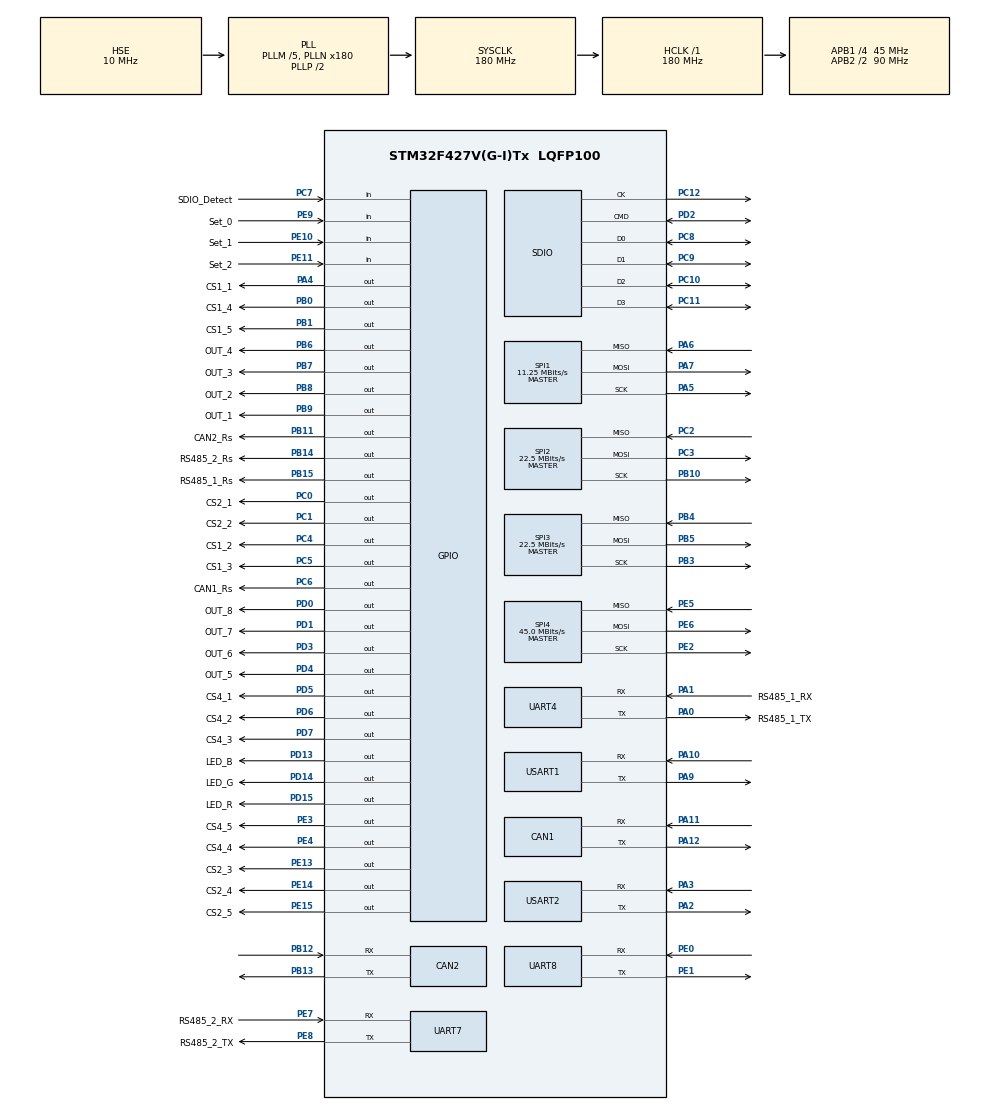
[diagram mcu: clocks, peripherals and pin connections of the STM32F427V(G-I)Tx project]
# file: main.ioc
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CAN1.BS1=CAN_BS1_1TQ
CAN1.BS2=CAN_BS2_1TQ
CAN1.CalculateTimeQuantum=355.55555555555554
CAN2.BS1=CAN_BS1_1TQ
CAN2.BS2=CAN_BS2_1TQ
CAN2.CalculateTimeQuantum=355.55555555555554
FATFS.BSP.number=1
FATFS0.BSP.STBoard=false
FATFS0.BSP.api=Unknown
FATFS0.BSP.i2caddr=0
FATFS0.BSP.instance=PC7
FATFS0.BSP.ip=GPIO
FATFS0.BSP.mode=Input
FATFS0.BSP.name=Detect_SDIO
FATFS0.BSP.solution=PC7
FREERTOS.Tasks01=defaultTask,0,128,StartDefaultTask,Default,NULL,Dynamic,NULL,NULL;ModBusTask,0,256,StartModBusTask,Default,NULL,Dynamic,NULL,NULL
Mcu.Family=STM32F4
Mcu.Name=STM32F427V(G-I)Tx
Mcu.Package=LQFP100
NVIC.PriorityGroup=NVIC_PRIORITYGROUP_4
NVIC.TIM2_IRQn=true\:5\:0\:false\:false\:true\:true\:true\:true
NVIC.TIM8_TRG_COM_TIM14_IRQn=true\:0\:0\:false\:false\:true\:false\:false\:true
NVIC.TimeBase=TIM8_TRG_COM_TIM14_IRQn
NVIC.TimeBaseIP=TIM14
NVIC.UART4_IRQn=true\:5\:0\:false\:false\:true\:true\:true\:true
NVIC.UART7_IRQn=true\:5\:0\:false\:false\:true\:true\:true\:true
PA0/WKUP.GPIO_Label=RS485_1_TX
PA0/WKUP.Mode=Asynchronous
PA0/WKUP.Signal=UART4_TX
PA1.GPIO_Label=RS485_1_RX
PA1.Mode=Asynchronous
PA1.Signal=UART4_RX
PA10.Mode=Asynchronous
PA10.Signal=USART1_RX
PA11.Mode=Master
PA11.Signal=CAN1_RX
PA12.Mode=Master
PA12.Signal=CAN1_TX
PA13.Mode=Serial_Wire
PA13.Signal=SYS_JTMS-SWDIO
PA14.Mode=Serial_Wire
PA14.Signal=SYS_JTCK-SWCLK
PA2.Mode=Asynchronous
PA2.Signal=USART2_TX
PA3.Mode=Asynchronous
PA3.Signal=USART2_RX
PA4.GPIO_Label=CS1_1
PA4.GPIO_Speed=GPIO_SPEED_FREQ_VERY_HIGH
PA4.PinState=GPIO_PIN_SET
PA4.Signal=GPIO_Output
PA5.Mode=Full_Duplex_Master
PA5.Signal=SPI1_SCK
PA6.Mode=Full_Duplex_Master
PA6.Signal=SPI1_MISO
PA7.Mode=Full_Duplex_Master
PA7.Signal=SPI1_MOSI
PA9.Mode=Asynchronous
PA9.Signal=USART1_TX
PB0.GPIO_Label=CS1_4
PB0.GPIO_Speed=GPIO_SPEED_FREQ_VERY_HIGH
PB0.PinState=GPIO_PIN_SET
PB0.Signal=GPIO_Output
PB1.GPIO_Label=CS1_5
PB1.GPIO_Speed=GPIO_SPEED_FREQ_VERY_HIGH
PB1.PinState=GPIO_PIN_SET
PB1.Signal=GPIO_Output
PB10.Mode=Full_Duplex_Master
PB10.Signal=SPI2_SCK
PB11.GPIO_Label=CAN2_Rs
PB11.Signal=GPIO_Output
PB12.Mode=Slave
PB12.Signal=CAN2_RX
PB13.Mode=Slave
PB13.Signal=CAN2_TX
PB14.GPIO_Label=RS485_2_Rs
PB14.GPIO_Speed=GPIO_SPEED_FREQ_VERY_HIGH
PB14.Signal=GPIO_Output
PB15.GPIO_Label=RS485_1_Rs
PB15.GPIO_Speed=GPIO_SPEED_FREQ_VERY_HIGH
PB15.Signal=GPIO_Output
PB3.Mode=Full_Duplex_Master
PB3.Signal=SPI3_SCK
PB4.Mode=Full_Duplex_Master
PB4.Signal=SPI3_MISO
PB5.Mode=Full_Duplex_Master
PB5.Signal=SPI3_MOSI
PB6.GPIO_Label=OUT_4
PB6.Signal=GPIO_Output
PB7.GPIO_Label=OUT_3
PB7.Signal=GPIO_Output
PB8.GPIO_Label=OUT_2
PB8.Signal=GPIO_Output
PB9.GPIO_Label=OUT_1
PB9.Signal=GPIO_Output
PC0.GPIO_Label=CS2_1
PC0.GPIO_Speed=GPIO_SPEED_FREQ_VERY_HIGH
PC0.PinState=GPIO_PIN_SET
PC0.Signal=GPIO_Output
PC1.GPIO_Label=CS2_2
PC1.GPIO_Speed=GPIO_SPEED_FREQ_VERY_HIGH
PC1.PinState=GPIO_PIN_SET
PC1.Signal=GPIO_Output
PC10.GPIO_PuPd=GPIO_PULLUP
PC10.Mode=SD_4_bits_Wide_bus
PC10.Signal=SDIO_D2
PC11.GPIO_PuPd=GPIO_PULLUP
PC11.Mode=SD_4_bits_Wide_bus
PC11.Signal=SDIO_D3
PC12.Mode=SD_4_bits_Wide_bus
PC12.Signal=SDIO_CK
PC14/OSC32_IN.Mode=LSE-External-Oscillator
PC14/OSC32_IN.Signal=RCC_OSC32_IN
PC15/OSC32_OUT.Mode=LSE-External-Oscillator
PC15/OSC32_OUT.Signal=RCC_OSC32_OUT
PC2.Mode=Full_Duplex_Master
PC2.Signal=SPI2_MISO
PC3.Mode=Full_Duplex_Master
PC3.Signal=SPI2_MOSI
PC4.GPIO_Label=CS1_2
PC4.GPIO_Speed=GPIO_SPEED_FREQ_VERY_HIGH
PC4.PinState=GPIO_PIN_SET
PC4.Signal=GPIO_Output
PC5.GPIO_Label=CS1_3
PC5.GPIO_Speed=GPIO_SPEED_FREQ_VERY_HIGH
PC5.PinState=GPIO_PIN_SET
PC5.Signal=GPIO_Output
PC6.GPIO_Label=CAN1_Rs
PC6.Signal=GPIO_Output
PC7.GPIO_Label=SDIO_Detect
PC7.GPIO_PuPd=GPIO_PULLUP
PC7.Signal=GPIO_Input
PC8.GPIO_PuPd=GPIO_PULLUP
PC8.Mode=SD_4_bits_Wide_bus
PC8.Signal=SDIO_D0
PC9.GPIO_PuPd=GPIO_PULLUP
PC9.Mode=SD_4_bits_Wide_bus
PC9.Signal=SDIO_D1
PD0.GPIO_Label=OUT_8
PD0.Signal=GPIO_Output
PD1.GPIO_Label=OUT_7
PD1.Signal=GPIO_Output
PD13.GPIO_Label=LED_B
PD13.PinState=GPIO_PIN_SET
PD13.Signal=GPIO_Output
PD14.GPIO_Label=LED_G
PD14.PinState=GPIO_PIN_RESET
PD14.Signal=GPIO_Output
PD15.GPIO_Label=LED_R
PD15.PinState=GPIO_PIN_SET
PD15.Signal=GPIO_Output
PD2.GPIO_PuPd=GPIO_PULLUP
PD2.Mode=SD_4_bits_Wide_bus
PD2.Signal=SDIO_CMD
PD3.GPIO_Label=OUT_6
PD3.Signal=GPIO_Output
PD4.GPIO_Label=OUT_5
PD4.Signal=GPIO_Output
PD5.GPIO_Label=CS4_1
PD5.GPIO_Speed=GPIO_SPEED_FREQ_VERY_HIGH
PD5.PinState=GPIO_PIN_SET
PD5.Signal=GPIO_Output
PD6.GPIO_Label=CS4_2
PD6.GPIO_Speed=GPIO_SPEED_FREQ_VERY_HIGH
PD6.PinState=GPIO_PIN_SET
PD6.Signal=GPIO_Output
PD7.GPIO_Label=CS4_3
PD7.GPIO_Speed=GPIO_SPEED_FREQ_VERY_HIGH
PD7.PinState=GPIO_PIN_SET
PD7.Signal=GPIO_Output
PE0.Mode=Asynchronous
PE0.Signal=UART8_RX
PE1.Mode=Asynchronous
PE1.Signal=UART8_TX
PE10.GPIO_Label=Set_1
PE10.GPIO_PuPd=GPIO_PULLUP
PE10.Signal=GPIO_Input
PE11.GPIO_Label=Set_2
PE11.GPIO_PuPd=GPIO_PULLUP
PE11.Signal=GPIO_Input
PE13.GPIO_Label=CS2_3
PE13.GPIO_Speed=GPIO_SPEED_FREQ_VERY_HIGH
PE13.PinState=GPIO_PIN_SET
PE13.Signal=GPIO_Output
PE14.GPIO_Label=CS2_4
PE14.GPIO_Speed=GPIO_SPEED_FREQ_VERY_HIGH
PE14.PinState=GPIO_PIN_SET
PE14.Signal=GPIO_Output
PE15.GPIO_Label=CS2_5
PE15.GPIO_Speed=GPIO_SPEED_FREQ_VERY_HIGH
PE15.PinState=GPIO_PIN_SET
PE15.Signal=GPIO_Output
PE2.Mode=Full_Duplex_Master
PE2.Signal=SPI4_SCK
PE3.GPIO_Label=CS4_5
PE3.GPIO_Speed=GPIO_SPEED_FREQ_VERY_HIGH
PE3.PinState=GPIO_PIN_SET
PE3.Signal=GPIO_Output
PE4.GPIO_Label=CS4_4
PE4.GPIO_Speed=GPIO_SPEED_FREQ_VERY_HIGH
PE4.PinState=GPIO_PIN_SET
PE4.Signal=GPIO_Output
PE5.Mode=Full_Duplex_Master
PE5.Signal=SPI4_MISO
PE6.Mode=Full_Duplex_Master
PE6.Signal=SPI4_MOSI
PE7.GPIO_Label=RS485_2_RX
PE7.Mode=Asynchronous
PE7.Signal=UART7_RX
PE8.GPIO_Label=RS485_2_TX
PE8.Mode=Asynchronous
PE8.Signal=UART7_TX
PE9.GPIO_Label=Set_0
PE9.GPIO_PuPd=GPIO_PULLUP
PE9.Signal=GPIO_Input
PH0/OSC_IN.Mode=HSE-External-Oscillator
PH0/OSC_IN.Signal=RCC_OSC_IN
PH1/OSC_OUT.Mode=HSE-External-Oscillator
PH1/OSC_OUT.Signal=RCC_OSC_OUT
ProjectManager.HeapSize=0x200
ProjectManager.StackSize=0x400
ProjectManager.TargetToolchain=MDK-ARM V5.27
RCC.48MHZClocksFreq_Value=45000000
RCC.AHBFreq_Value=180000000
RCC.APB1CLKDivider=RCC_HCLK_DIV4
RCC.APB1Freq_Value=45000000
RCC.APB1TimFreq_Value=90000000
RCC.APB2CLKDivider=RCC_HCLK_DIV2
RCC.APB2Freq_Value=90000000
RCC.APB2TimFreq_Value=180000000
RCC.CortexFreq_Value=180000000
RCC.HCLKFreq_Value=180000000
RCC.HSE_VALUE=10000000
RCC.HSI_VALUE=16000000
RCC.PLLM=5
RCC.PLLN=180
RCC.PLLQ=8
RCC.PLLSourceVirtual=RCC_PLLSOURCE_HSE
RCC.SYSCLKFreq_VALUE=180000000
RCC.SYSCLKSource=RCC_SYSCLKSOURCE_PLLCLK
RCC.VCOOutputFreq_Value=360000000
SPI1.BaudRatePrescaler=SPI_BAUDRATEPRESCALER_8
SPI1.CalculateBaudRate=11.25 MBits/s
SPI1.Direction=SPI_DIRECTION_2LINES
SPI1.Mode=SPI_MODE_MASTER
SPI1.VirtualType=VM_MASTER
SPI2.BaudRatePrescaler=SPI_BAUDRATEPRESCALER_2
SPI2.CalculateBaudRate=22.5 MBits/s
SPI2.Direction=SPI_DIRECTION_2LINES
SPI2.Mode=SPI_MODE_MASTER
SPI2.VirtualType=VM_MASTER
SPI3.BaudRatePrescaler=SPI_BAUDRATEPRESCALER_2
SPI3.CalculateBaudRate=22.5 MBits/s
SPI3.Direction=SPI_DIRECTION_2LINES
SPI3.Mode=SPI_MODE_MASTER
SPI3.VirtualType=VM_MASTER
SPI4.BaudRatePrescaler=SPI_BAUDRATEPRESCALER_2
SPI4.CalculateBaudRate=45.0 MBits/s
SPI4.Direction=SPI_DIRECTION_2LINES
SPI4.Mode=SPI_MODE_MASTER
SPI4.VirtualType=VM_MASTER
UART4.VirtualMode=Asynchronous
UART7.VirtualMode=Asynchronous
UART8.VirtualMode=Asynchronous
USART1.VirtualMode=VM_ASYNC
USART2.VirtualMode=VM_ASYNC
VP_FATFS_VS_SDIO.Mode=SDIO
VP_FREERTOS_VS_CMSIS_V1.Mode=CMSIS_V1
VP_SYS_VS_tim14.Mode=TIM14
VP_TIM2_VS_ClockSourceINT.Mode=Internal
board=custom

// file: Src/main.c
/* USER CODE BEGIN Header */
/**
  ******************************************************************************
  * @file           : main.c
  * @brief          : Main program body
  ******************************************************************************
  * @attention
  *
  * <h2><center>&copy; Copyright (c) 2020 STMicroelectronics.
  * All rights reserved.</center></h2>
  *
  * This software component is licensed by ST under Ultimate Liberty license
  * SLA0044, the "License"; You may not use this file except in compliance with
  * the License. You may obtain a copy of the License at:
  *                             www.st.com/SLA0044
  *
  ******************************************************************************
  */
/* USER CODE END Header */

#include "main.h"
#include "cmsis_os.h"
#include "can.h"
#include "fatfs.h"
#include "sdio.h"
#include "spi.h"
#include "tim.h"
#include "usart.h"
#include "gpio.h"

void SystemClock_Config(void);
void MX_FREERTOS_Init(void);

int main(void)
{

  /* MCU Configuration--------------------------------------------------------*/

  /* Reset of all peripherals, Initializes the Flash interface and the Systick. */
  HAL_Init();

  /* Configure the system clock */
  SystemClock_Config();

  /* Initialize all configured peripherals */
  MX_GPIO_Init();
  MX_CAN1_Init();
  MX_CAN2_Init();
  MX_SPI1_Init();
  MX_SPI2_Init();
  MX_SPI3_Init();
  MX_SPI4_Init();
  MX_UART4_Init();
  MX_UART7_Init();
  MX_UART8_Init();
  MX_USART1_UART_Init();
  MX_USART2_UART_Init();
  MX_SDIO_SD_Init();
  MX_FATFS_Init();
  MX_TIM2_Init();

  /* Call init function for freertos objects (in freertos.c) */
  MX_FREERTOS_Init();
  /* Start scheduler */
  osKernelStart();

  /* We should never get here as control is now taken by the scheduler */
  /* Infinite loop */
  while (1)
  {

  }
}

void SystemClock_Config(void)
{
  RCC_OscInitTypeDef RCC_OscInitStruct = {0};
  RCC_ClkInitTypeDef RCC_ClkInitStruct = {0};

  /** Configure the main internal regulator output voltage
  */
  __HAL_RCC_PWR_CLK_ENABLE();
  __HAL_PWR_VOLTAGESCALING_CONFIG(PWR_REGULATOR_VOLTAGE_SCALE1);
  /** Initializes the CPU, AHB and APB busses clocks
  */
  RCC_OscInitStruct.OscillatorType = RCC_OSCILLATORTYPE_HSE;
  RCC_OscInitStruct.HSEState = RCC_HSE_ON;
  RCC_OscInitStruct.PLL.PLLState = RCC_PLL_ON;
  RCC_OscInitStruct.PLL.PLLSource = RCC_PLLSOURCE_HSE;
  RCC_OscInitStruct.PLL.PLLM = 5;
  RCC_OscInitStruct.PLL.PLLN = 180;
  RCC_OscInitStruct.PLL.PLLP = RCC_PLLP_DIV2;
  RCC_OscInitStruct.PLL.PLLQ = 8;
  if (HAL_RCC_OscConfig(&RCC_OscInitStruct) != HAL_OK)
  {
    Error_Handler();
  }
  /** Activate the Over-Drive mode
  */
  if (HAL_PWREx_EnableOverDrive() != HAL_OK)
  {
    Error_Handler();
  }
  /** Initializes the CPU, AHB and APB busses clocks
  */
  RCC_ClkInitStruct.ClockType = RCC_CLOCKTYPE_HCLK|RCC_CLOCKTYPE_SYSCLK
                              |RCC_CLOCKTYPE_PCLK1|RCC_CLOCKTYPE_PCLK2;
  RCC_ClkInitStruct.SYSCLKSource = RCC_SYSCLKSOURCE_PLLCLK;
  RCC_ClkInitStruct.AHBCLKDivider = RCC_SYSCLK_DIV1;
  RCC_ClkInitStruct.APB1CLKDivider = RCC_HCLK_DIV4;
  RCC_ClkInitStruct.APB2CLKDivider = RCC_HCLK_DIV2;

  if (HAL_RCC_ClockConfig(&RCC_ClkInitStruct, FLASH_LATENCY_5) != HAL_OK)
  {
    Error_Handler();
  }
}

 /**
  * @brief  Period elapsed callback in non blocking mode
  * @note   This function is called  when TIM14 interrupt took place, inside
  * HAL_TIM_IRQHandler(). It makes a direct call to HAL_IncTick() to increment
  * a global variable "uwTick" used as application time base.
  * @param  htim : TIM handle
  * @retval None
  */
void HAL_TIM_PeriodElapsedCallback(TIM_HandleTypeDef *htim)
{
  if (htim->Instance == TIM14) {
    HAL_IncTick();
  }
}

void Error_Handler(void)
{
}

/************************ (C) COPYRIGHT STMicroelectronics *****END OF FILE****/

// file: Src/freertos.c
/* USER CODE BEGIN Header */
/**
  ******************************************************************************
  * File Name          : freertos.c
  * Description        : Code for freertos applications
  ******************************************************************************
  * @attention
  *
  * <h2><center>&copy; Copyright (c) 2020 STMicroelectronics.
  * All rights reserved.</center></h2>
  *
  * This software component is licensed by ST under Ultimate Liberty license
  * SLA0044, the "License"; You may not use this file except in compliance with
  * the License. You may obtain a copy of the License at:
  *                             www.st.com/SLA0044
  *
  ******************************************************************************
  */
/* USER CODE END Header */

#include "FreeRTOS.h"
#include "task.h"
#include "main.h"
#include "cmsis_os.h"

/* USER CODE BEGIN Includes */
//#include "user_mb_app.h"
#include "mb.h"
//#include "mb_m.h"
#include "mbport.h"
#include "DescriptMotorControl.h"
/* USER CODE END Includes */

/* USER CODE BEGIN PD */
//адреса регистров modbus
#define REG_HOLDING_START 0x0000
#define REG_HOLDING_NREGS 8
#define REG_SETTINGS_START REG_HOLDING_START + REG_HOLDING_NREGS//0x0008
#define REG_SETTINGS_NREGS 16
//#define RECEIV_INPUT_START REG_SETTINGS_START + REG_SETTINGS_NREGS//0x0018
//#define RECEIV_INPUT_NREGS 8

// карта регистров настройки
#define REG_BaudRate_START        REG_SETTINGS_START
#define REG_Mode_START            REG_BaudRate_START + 2
#define REG_SlaveAddress_START    REG_Mode_START + 1
#define REG_Role_START            REG_SlaveAddress_START + 1
#define REG_WriteInEEPROM_START   15

/* USER CODE END PD */

/* USER CODE BEGIN Variables */
extern SPI_HandleTypeDef hspi1;
//extern USHORT   usMRegHoldBuf[MB_MASTER_TOTAL_SLAVE_NUM][M_REG_HOLDING_NREGS];

int start = 0;

//static USHORT usRegHoldingStart = REG_HOLDING_START;
//static USHORT usRegHoldingBuf[REG_HOLDING_NREGS] = {0};

//static USHORT usRegSettingsStart = REG_SETTINGS_START;
//static USHORT usRegSettingsBuf[REG_SETTINGS_NREGS] = {0};

/* USER CODE END Variables */
osThreadId defaultTaskHandle;
osThreadId ModBusTaskHandle;

void StartDefaultTask(void const * argument);
void StartModBusTask(void const * argument);

void MX_FREERTOS_Init(void); /* (MISRA C 2004 rule 8.1) */

/* GetIdleTaskMemory prototype (linked to static allocation support) */
void vApplicationGetIdleTaskMemory( StaticTask_t **ppxIdleTaskTCBBuffer, StackType_t **ppxIdleTaskStackBuffer, uint32_t *pulIdleTaskStackSize );

/* USER CODE BEGIN GET_IDLE_TASK_MEMORY */
static StaticTask_t xIdleTaskTCBBuffer;
static StackType_t xIdleStack[configMINIMAL_STACK_SIZE];

void vApplicationGetIdleTaskMemory( StaticTask_t **ppxIdleTaskTCBBuffer, StackType_t **ppxIdleTaskStackBuffer, uint32_t *pulIdleTaskStackSize )
{
  *ppxIdleTaskTCBBuffer = &xIdleTaskTCBBuffer;
  *ppxIdleTaskStackBuffer = &xIdleStack[0];
  *pulIdleTaskStackSize = configMINIMAL_STACK_SIZE;
  /* place for user code */
}
/* USER CODE END GET_IDLE_TASK_MEMORY */

void MX_FREERTOS_Init(void) {

  /* Create the thread(s) */
  /* definition and creation of defaultTask */
  osThreadDef(defaultTask, StartDefaultTask, osPriorityNormal, 0, 128);
  defaultTaskHandle = osThreadCreate(osThread(defaultTask), NULL);

  /* definition and creation of ModBusTask */
  osThreadDef(ModBusTask, StartModBusTask, osPriorityNormal, 0, 256);
  ModBusTaskHandle = osThreadCreate(osThread(ModBusTask), NULL);

}

void StartDefaultTask(void const * argument)
{
  /* USER CODE BEGIN StartDefaultTask */
  /* Infinite loop */
  for(;;)
  {
    if (start)
    {

    }
    osDelay(1);
  }
  /* USER CODE END StartDefaultTask */
}

void StartModBusTask(void const * argument)
{
  /* USER CODE BEGIN StartModBusTask */
  eMBErrorCode eStatus = eMBInit( MB_RTU, 11, 3, 115200, MB_PAR_NONE );
  eStatus = eMBEnable();

  /* Infinite loop */
  for(;;)
  {
    eStatus = eMBPoll();

    osDelay(1);
  }
  /* USER CODE END StartModBusTask */
}

/* USER CODE BEGIN Application */

/*description https://www.freemodbus.org/api/group__modbus__registers.html*/
//0x04
eMBErrorCode
eMBRegInputCB( UCHAR * pucRegBuffer, USHORT usAddress, USHORT usNRegs )
{
    if(usAddress == 0 ){}
    else{usAddress--;}

    eMBErrorCode    eStatus = MB_ENOERR;
//    int             iRegIndex;

//    if( ( usAddress >= RECEIV_INPUT_START ) && ( usAddress + usNRegs >= RECEIV_INPUT_START + RECEIV_INPUT_NREGS ) )
//    {
//        iRegIndex = ( int )( usAddress - ReceivInputStart );
//
//        osMutexWait(mutex_modbusHandle, 10);
//        while( usNRegs > 0 )
//        {
//			// проверить правилность упаковки байтов
//            *pucRegBuffer++ = ( unsigned char )( ReceivInputBuf[iRegIndex] >> 8 );
//            *pucRegBuffer++ = ( unsigned char )( ReceivInputBuf[iRegIndex] & 0xFF );
//            iRegIndex++;
//            usNRegs--;
//        }
//        osMutexRelease(mutex_modbusHandle);
//	//HAL_GPIO_TogglePin(User_LED_GPIO_Port, User_LED_Pin);
//    }
//    else
    {
	//HAL_GPIO_TogglePin(User_LED_GPIO_Port, User_LED_Pin);
        eStatus = MB_ENOREG;
    }

    return eStatus;
}
//0x03 0x06 0x10
eMBErrorCode
eMBRegHoldingCB( UCHAR * pucRegBuffer, USHORT usAddress, USHORT usNRegs, eMBRegisterMode eMode )
{
    uint8_t CMD[5] = {0};
    volatile HAL_StatusTypeDef status;

    if(usAddress == 0 ){}
    else{usAddress--;}

    eMBErrorCode    eStatus = MB_ENOERR;

//    if(( (int)usAddress >= REG_HOLDING_START ) && ( usAddress + usNRegs <= REG_HOLDING_START + REG_HOLDING_NREGS ))
//    {
////      eStatus = mbCB_inputsReg(pucRegBuffer, usAddress, usNRegs, eMode);
//    }
//    // продумать чтение и запись сразу всех регистров
//    else if (( usAddress >= usRegSettingsStart ) && ( usAddress + usNRegs <= REG_SETTINGS_START + REG_SETTINGS_NREGS) ) // настройка регистров modbus
//    {
////    eStatus = mbCB_eeprom(pucRegBuffer, usAddress, usNRegs, eMode);
//    }
//    else
//    {
//      eStatus = MB_ENOREG;
//    }

    // переключатель чтение запись
    switch (eMode)
    {
      case MB_REG_READ:
      {
        break;
      }
      case MB_REG_WRITE:
      {
        //переключатель по адресам регистра
        switch (usAddress)
        {
          case 0:
          {
            // команды для отправки на мотор
            switch (*(pucRegBuffer+1))
            {
              case START:
              {
                CMD[0] = START;
                HAL_GPIO_WritePin(CS1_1_GPIO_Port, CS1_1_Pin, GPIO_PIN_RESET);
                status = HAL_SPI_Transmit(&hspi1, CMD, 5, 100);
                HAL_GPIO_WritePin(CS1_1_GPIO_Port, CS1_1_Pin, GPIO_PIN_SET);

                break;
              }
              case STOP:
              {
                CMD[0] = STOP;
                HAL_GPIO_WritePin(CS1_1_GPIO_Port, CS1_1_Pin, GPIO_PIN_RESET);
                status = HAL_SPI_Transmit(&hspi1, CMD, 5, 100);
                HAL_GPIO_WritePin(CS1_1_GPIO_Port, CS1_1_Pin, GPIO_PIN_SET);

                break;
              }
              case LEFT:
              {
                CMD[0] = LEFT;
                HAL_GPIO_WritePin(CS1_1_GPIO_Port, CS1_1_Pin, GPIO_PIN_RESET);
                status = HAL_SPI_Transmit(&hspi1, CMD, 5, 100);
                HAL_GPIO_WritePin(CS1_1_GPIO_Port, CS1_1_Pin, GPIO_PIN_SET);

                break;
              }
              case RIGHT:
              {
                CMD[0] = RIGHT;
                HAL_GPIO_WritePin(CS1_1_GPIO_Port, CS1_1_Pin, GPIO_PIN_RESET);
                status = HAL_SPI_Transmit(&hspi1, CMD, 5, 100);
                HAL_GPIO_WritePin(CS1_1_GPIO_Port, CS1_1_Pin, GPIO_PIN_SET);

                break;
              }
              default:
              {

                break;
              }
            }
            break;
          }
          case 1:
          {
            break;
          }
          default:
          {
            eStatus = MB_ENOREG;
            break;
          }
        }

        break;
      }
      default:
      {
        eStatus = MB_EINVAL;
        break;
      }
    }

    return eStatus;
}

// 0x01 0x0f 0x05
eMBErrorCode
eMBRegCoilsCB( UCHAR * pucRegBuffer, USHORT usAddress, USHORT usNCoils, eMBRegisterMode eMode )
{
    if(usAddress == 0 ){}
    else{usAddress--;}

    return MB_ENOREG;
}
//0x02
eMBErrorCode
eMBRegDiscreteCB( UCHAR * pucRegBuffer, USHORT usAddress, USHORT usNDiscrete )
{
    if(usAddress == 0 ){}
    else{usAddress--;}

    return MB_ENOREG;
}
/* USER CODE END Application */

/************************ (C) COPYRIGHT STMicroelectronics *****END OF FILE****/
